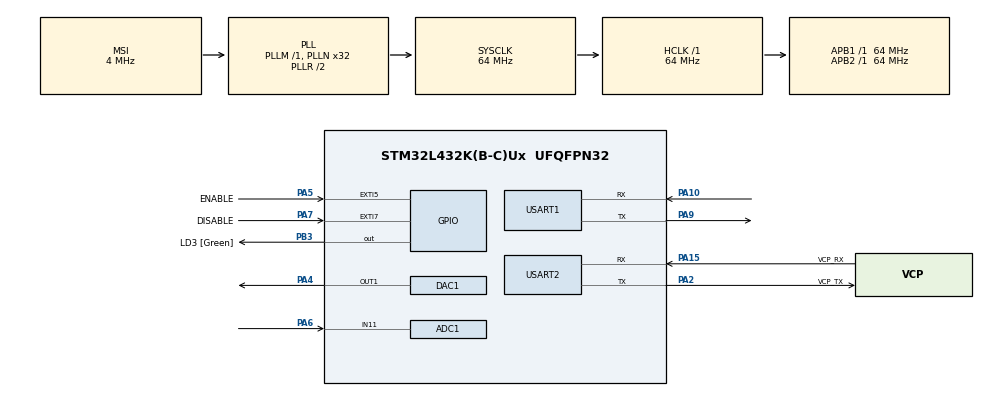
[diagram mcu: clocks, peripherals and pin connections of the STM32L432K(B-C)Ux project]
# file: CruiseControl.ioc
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ADC1.Channel-1\#ChannelRegularConversion=ADC_CHANNEL_11
ADC1.NbrOfConversionFlag=1
ADC1.OffsetNumber-1\#ChannelRegularConversion=ADC_OFFSET_NONE
ADC1.Rank-1\#ChannelRegularConversion=1
ADC1.SamplingTime-1\#ChannelRegularConversion=ADC_SAMPLETIME_2CYCLES_5
ADC1.master=1
Mcu.Family=STM32L4
Mcu.Name=STM32L432K(B-C)Ux
Mcu.Package=UFQFPN32
NVIC.PriorityGroup=NVIC_PRIORITYGROUP_4
PA0.GPIO_Label=MCO [High speed clock in]
PA0.Mode=HSE-External-Clock-Source-for-LittleOrca
PA0.Signal=RCC_CK_IN
PA10.Mode=Asynchronous
PA10.Signal=USART1_RX
PA13\ (JTMS-SWDIO).GPIO_Label=SWDIO
PA13\ (JTMS-SWDIO).Mode=Serial_Wire
PA13\ (JTMS-SWDIO).Signal=SYS_JTMS-SWDIO
PA14\ (JTCK-SWCLK).GPIO_Label=SWCLK
PA14\ (JTCK-SWCLK).Mode=Serial_Wire
PA14\ (JTCK-SWCLK).Signal=SYS_JTCK-SWCLK
PA15\ (JTDI).GPIO_Label=VCP_RX
PA15\ (JTDI).Mode=Asynchronous
PA15\ (JTDI).Signal=USART2_RX
PA2.GPIO_Label=VCP_TX
PA2.Mode=Asynchronous
PA2.Signal=USART2_TX
PA4.Signal=COMP_DAC11_group
PA5.GPIO_Label=ENABLE
PA5.GPIO_PuPd=GPIO_PULLDOWN
PA5.Signal=GPXTI5
PA6.Signal=ADCx_IN11
PA7.GPIO_Label=DISABLE
PA7.Signal=GPXTI7
PA9.Mode=Asynchronous
PA9.Signal=USART1_TX
PB3\ (JTDO-TRACESWO).GPIO_Label=LD3 [Green]
PB3\ (JTDO-TRACESWO).Signal=GPIO_Output
PC14-OSC32_IN\ (PC14).Mode=LSE-External-Oscillator
PC14-OSC32_IN\ (PC14).Signal=RCC_OSC32_IN
PC15-OSC32_OUT\ (PC15).Mode=LSE-External-Oscillator
PC15-OSC32_OUT\ (PC15).Signal=RCC_OSC32_OUT
ProjectManager.HeapSize=0x200
ProjectManager.StackSize=0x400
ProjectManager.TargetToolchain=STM32CubeIDE
RCC.ADCFreq_Value=32000000
RCC.AHBFreq_Value=64000000
RCC.APB1Freq_Value=64000000
RCC.APB1TimFreq_Value=64000000
RCC.APB2Freq_Value=64000000
RCC.APB2TimFreq_Value=64000000
RCC.CortexFreq_Value=64000000
RCC.HCLKFreq_Value=64000000
RCC.HSE_VALUE=8000000
RCC.HSI16_VALUE=16000000
RCC.HSI48_VALUE=48000000
RCC.HSI_VALUE=16000000
RCC.MSI_VALUE=4000000
RCC.PLLMUL=RCC_PLLMUL_4
RCC.PLLN=32
RCC.PLLSAI1N=16
RCC.SYSCLKFreq_VALUE=64000000
RCC.SYSCLKSource=RCC_SYSCLKSOURCE_PLLCLK
RCC.USBFreq_Value=32000000
RCC.VCOOutputFreq_Value=128000000
SH.ADCx_IN11.0=ADC1_IN11,IN11-Single-Ended
SH.COMP_DAC11_group.0=DAC1_OUT1,DAC_OUT1
USART1.VirtualMode-Asynchronous=VM_ASYNC
USART2.VirtualMode-Asynchronous=VM_ASYNC
board=NUCLEO-L432KC

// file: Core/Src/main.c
/* USER CODE BEGIN Header */
/**
  ******************************************************************************
  * @file           : main.c
  * @brief          : Main program body
  ******************************************************************************
  * @attention
  *
  * Copyright (c) 2022 STMicroelectronics.
  * All rights reserved.
  *
  * This software is licensed under terms that can be found in the LICENSE file
  * in the root directory of this software component.
  * If no LICENSE file comes with this software, it is provided AS-IS.
  *
  ******************************************************************************
  */
/* USER CODE END Header */
#include "main.h"
#include "commands_ELM.h"
#include "throttle.h"
#include "stdio.h"
#include "elm327.h"

volatile ADC_HandleTypeDef hadc1;

volatile DAC_HandleTypeDef hdac1;

UART_HandleTypeDef huart1;
UART_HandleTypeDef huart2;

/* USER CODE BEGIN PV */
volatile car_t car_controler;
volatile elm_t dongle;
volatile pid_controller_t pid;

volatile char receive_buffer[64];
/* USER CODE END PV */

void SystemClock_Config(void);
static void MX_GPIO_Init(void);
static void MX_USART2_UART_Init(void);
static void MX_ADC1_Init(void);
static void MX_DAC1_Init(void);
static void MX_USART1_UART_Init(void);

/* USER CODE BEGIN 0 */

int __io_putchar(int ch) {
    uint8_t msg = ch;
    HAL_UART_Transmit(&huart2, &msg, 1, 1000);
    return 1;
}

void timer_configuire()
{

    __HAL_RCC_TIM2_CLK_ENABLE();

    HAL_NVIC_SetPriority(TIM2_IRQn,0,0);
    HAL_NVIC_EnableIRQ(TIM2_IRQn);

    TIM_TypeDef * timer = TIM2;
    timer->EGR = TIM_EGR_UG;
    timer->PSC = 64-1;
    timer->ARR = 5000;
    timer->CR1 = TIM_CR1_ARPE | TIM_CR1_CEN;
    TIM2->DIER =  TIM_DIER_UIE; //generate interrupts

}
/* USER CODE END 0 */

int main(void)
{

  /* MCU Configuration--------------------------------------------------------*/

  /* Reset of all peripherals, Initializes the Flash interface and the Systick. */
  HAL_Init();

  /* Configure the system clock */
  SystemClock_Config();

  /* Initialize all configured peripherals */
  MX_GPIO_Init();
  MX_USART2_UART_Init();
  MX_ADC1_Init();
  MX_DAC1_Init();
  MX_USART1_UART_Init();

  /* USER CODE BEGIN 2 */

    car_controler.throttle_dac_handler = &hdac1;
    car_controler.accelerator_adc_handler = &hadc1;
    car_controler.controler_engaged = 1;
    car_controler.ecu_en_pin = PEDAL_EN_Pin;
    car_controler.ecu_en_port = PEDAL_EN_Port;
    car_controler.state = CAR_STATUS_DIRECT;
    car_controler.controller = &pid;

    HAL_DAC_Start(&hdac1,0);
    HAL_ADC_Start(&hadc1);

    timer_configuire();
  /* USER CODE END 2 */

  /* Infinite loop */
  /* USER CODE BEGIN WHILE */
    car_throttle_handler(&car_controler);

    dongle.huart = &huart1;
    HAL_Delay(2000);
    elm_connect(&dongle);

dongle.rec_buf = receive_buffer;
    for(int i = 0; i<64; i++)
    {
        dongle.rec_buf[i]=0;
    }
    dongle.rec_buf[63] = '\n';

  while (1)
  {

      elm_send_query(&dongle,ELM_QUERY_SPEED,sizeof ELM_QUERY_SPEED,ELM_QUERY_SPEED_DATA_SIZE);

      HAL_Delay(1000);

      printf("Received: %s \r\n", dongle.rec_buf);
      if(dongle.valid_reading) {
          printf("\r\n Speed: %d \r\n", dongle.current_speed);
      }

      /* USER CODE END WHILE */

  }
}

void SystemClock_Config(void)
{
  RCC_OscInitTypeDef RCC_OscInitStruct = {0};
  RCC_ClkInitTypeDef RCC_ClkInitStruct = {0};

  /** Configure the main internal regulator output voltage
  */
  if (HAL_PWREx_ControlVoltageScaling(PWR_REGULATOR_VOLTAGE_SCALE1) != HAL_OK)
  {
    Error_Handler();
  }

  /** Configure LSE Drive Capability
  */
  HAL_PWR_EnableBkUpAccess();
  __HAL_RCC_LSEDRIVE_CONFIG(RCC_LSEDRIVE_LOW);

  /** Initializes the RCC Oscillators according to the specified parameters
  * in the RCC_OscInitTypeDef structure.
  */
  RCC_OscInitStruct.OscillatorType = RCC_OSCILLATORTYPE_LSE|RCC_OSCILLATORTYPE_MSI;
  RCC_OscInitStruct.LSEState = RCC_LSE_ON;
  RCC_OscInitStruct.MSIState = RCC_MSI_ON;
  RCC_OscInitStruct.MSICalibrationValue = 0;
  RCC_OscInitStruct.MSIClockRange = RCC_MSIRANGE_6;
  RCC_OscInitStruct.PLL.PLLState = RCC_PLL_ON;
  RCC_OscInitStruct.PLL.PLLSource = RCC_PLLSOURCE_MSI;
  RCC_OscInitStruct.PLL.PLLM = 1;
  RCC_OscInitStruct.PLL.PLLN = 32;
  RCC_OscInitStruct.PLL.PLLP = RCC_PLLP_DIV7;
  RCC_OscInitStruct.PLL.PLLQ = RCC_PLLQ_DIV2;
  RCC_OscInitStruct.PLL.PLLR = RCC_PLLR_DIV2;
  if (HAL_RCC_OscConfig(&RCC_OscInitStruct) != HAL_OK)
  {
    Error_Handler();
  }

  /** Initializes the CPU, AHB and APB buses clocks
  */
  RCC_ClkInitStruct.ClockType = RCC_CLOCKTYPE_HCLK|RCC_CLOCKTYPE_SYSCLK
                              |RCC_CLOCKTYPE_PCLK1|RCC_CLOCKTYPE_PCLK2;
  RCC_ClkInitStruct.SYSCLKSource = RCC_SYSCLKSOURCE_PLLCLK;
  RCC_ClkInitStruct.AHBCLKDivider = RCC_SYSCLK_DIV1;
  RCC_ClkInitStruct.APB1CLKDivider = RCC_HCLK_DIV1;
  RCC_ClkInitStruct.APB2CLKDivider = RCC_HCLK_DIV1;

  if (HAL_RCC_ClockConfig(&RCC_ClkInitStruct, FLASH_LATENCY_3) != HAL_OK)
  {
    Error_Handler();
  }

  /** Enable MSI Auto calibration
  */
  HAL_RCCEx_EnableMSIPLLMode();
}

static void MX_ADC1_Init(void)
{

  ADC_ChannelConfTypeDef sConfig = {0};

  /** Common config
  */
  hadc1.Instance = ADC1;
  hadc1.Init.ClockPrescaler = ADC_CLOCK_ASYNC_DIV1;
  hadc1.Init.Resolution = ADC_RESOLUTION_12B;
  hadc1.Init.DataAlign = ADC_DATAALIGN_RIGHT;
  hadc1.Init.ScanConvMode = ADC_SCAN_DISABLE;
  hadc1.Init.EOCSelection = ADC_EOC_SINGLE_CONV;
  hadc1.Init.LowPowerAutoWait = DISABLE;
  hadc1.Init.ContinuousConvMode = DISABLE;
  hadc1.Init.NbrOfConversion = 1;
  hadc1.Init.DiscontinuousConvMode = DISABLE;
  hadc1.Init.ExternalTrigConv = ADC_SOFTWARE_START;
  hadc1.Init.ExternalTrigConvEdge = ADC_EXTERNALTRIGCONVEDGE_NONE;
  hadc1.Init.DMAContinuousRequests = DISABLE;
  hadc1.Init.Overrun = ADC_OVR_DATA_PRESERVED;
  hadc1.Init.OversamplingMode = DISABLE;
  if (HAL_ADC_Init(&hadc1) != HAL_OK)
  {
    Error_Handler();
  }

  /** Configure Regular Channel
  */
  sConfig.Channel = ADC_CHANNEL_11;
  sConfig.Rank = ADC_REGULAR_RANK_1;
  sConfig.SamplingTime = ADC_SAMPLETIME_2CYCLES_5;
  sConfig.SingleDiff = ADC_SINGLE_ENDED;
  sConfig.OffsetNumber = ADC_OFFSET_NONE;
  sConfig.Offset = 0;
  if (HAL_ADC_ConfigChannel(&hadc1, &sConfig) != HAL_OK)
  {
    Error_Handler();
  }

}

static void MX_DAC1_Init(void)
{

  DAC_ChannelConfTypeDef sConfig = {0};

  /** DAC Initialization
  */
  hdac1.Instance = DAC1;
  if (HAL_DAC_Init(&hdac1) != HAL_OK)
  {
    Error_Handler();
  }

  /** DAC channel OUT1 config
  */
  sConfig.DAC_SampleAndHold = DAC_SAMPLEANDHOLD_DISABLE;
  sConfig.DAC_Trigger = DAC_TRIGGER_NONE;
  sConfig.DAC_OutputBuffer = DAC_OUTPUTBUFFER_ENABLE;
  sConfig.DAC_ConnectOnChipPeripheral = DAC_CHIPCONNECT_DISABLE;
  sConfig.DAC_UserTrimming = DAC_TRIMMING_FACTORY;
  if (HAL_DAC_ConfigChannel(&hdac1, &sConfig, DAC_CHANNEL_1) != HAL_OK)
  {
    Error_Handler();
  }

}

static void MX_USART1_UART_Init(void)
{

  /* USER CODE BEGIN USART1_Init 0 */
    HAL_NVIC_SetPriority(USART1_IRQn, 2, 2);
    HAL_NVIC_EnableIRQ(USART1_IRQn);
  /* USER CODE END USART1_Init 0 */

  huart1.Instance = USART1;
  huart1.Init.BaudRate = 9600;
  huart1.Init.WordLength = UART_WORDLENGTH_8B;
  huart1.Init.StopBits = UART_STOPBITS_1;
  huart1.Init.Parity = UART_PARITY_NONE;
  huart1.Init.Mode = UART_MODE_TX_RX;
  huart1.Init.HwFlowCtl = UART_HWCONTROL_NONE;
  huart1.Init.OverSampling = UART_OVERSAMPLING_16;
  huart1.Init.OneBitSampling = UART_ONE_BIT_SAMPLE_DISABLE;
  huart1.AdvancedInit.AdvFeatureInit = UART_ADVFEATURE_NO_INIT;
  if (HAL_UART_Init(&huart1) != HAL_OK)
  {
    Error_Handler();
  }

}

static void MX_USART2_UART_Init(void)
{

  huart2.Instance = USART2;
  huart2.Init.BaudRate = 9600;
  huart2.Init.WordLength = UART_WORDLENGTH_8B;
  huart2.Init.StopBits = UART_STOPBITS_1;
  huart2.Init.Parity = UART_PARITY_NONE;
  huart2.Init.Mode = UART_MODE_TX_RX;
  huart2.Init.HwFlowCtl = UART_HWCONTROL_NONE;
  huart2.Init.OverSampling = UART_OVERSAMPLING_16;
  huart2.Init.OneBitSampling = UART_ONE_BIT_SAMPLE_DISABLE;
  huart2.AdvancedInit.AdvFeatureInit = UART_ADVFEATURE_NO_INIT;
  if (HAL_UART_Init(&huart2) != HAL_OK)
  {
    Error_Handler();
  }

}

static void MX_GPIO_Init(void)
{
  GPIO_InitTypeDef GPIO_InitStruct = {0};

  /* GPIO Ports Clock Enable */
  __HAL_RCC_GPIOC_CLK_ENABLE();
  __HAL_RCC_GPIOA_CLK_ENABLE();
  __HAL_RCC_GPIOB_CLK_ENABLE();

  /*Configure GPIO pin Output Level */
  HAL_GPIO_WritePin(LD3_GPIO_Port, LD3_Pin, GPIO_PIN_RESET);

  /*Configure GPIO pin : ENABLE_Pin */
  GPIO_InitStruct.Pin = ENABLE_Pin;
  GPIO_InitStruct.Mode = GPIO_MODE_IT_RISING;
  GPIO_InitStruct.Pull = GPIO_PULLUP;
  HAL_GPIO_Init(ENABLE_GPIO_Port, &GPIO_InitStruct);

  /*Configure GPIO pin : DISABLE_Pin */
  GPIO_InitStruct.Pin = DISABLE_Pin;
  GPIO_InitStruct.Mode = GPIO_MODE_IT_RISING;
  GPIO_InitStruct.Pull = GPIO_PULLUP;
  HAL_GPIO_Init(DISABLE_GPIO_Port, &GPIO_InitStruct);

  /*Configure GPIO pin : LD3_Pin */
  GPIO_InitStruct.Pin = LD3_Pin;
  GPIO_InitStruct.Mode = GPIO_MODE_OUTPUT_PP;
  GPIO_InitStruct.Pull = GPIO_NOPULL;
  GPIO_InitStruct.Speed = GPIO_SPEED_FREQ_LOW;
  HAL_GPIO_Init(LD3_GPIO_Port, &GPIO_InitStruct);

    GPIO_InitStruct.Pin = PEDAL_EN_Pin;
    GPIO_InitStruct.Mode = GPIO_MODE_OUTPUT_PP;
    GPIO_InitStruct.Pull = GPIO_NOPULL;
    GPIO_InitStruct.Speed = GPIO_SPEED_FREQ_LOW;
    HAL_GPIO_Init(PEDAL_EN_Port, &GPIO_InitStruct);

    HAL_NVIC_SetPriority(EXTI9_5_IRQn,0,0);
    HAL_NVIC_EnableIRQ(EXTI9_5_IRQn);

}

/* USER CODE BEGIN 4 */
void TIM2_IRQHandler(void)  //main refresh loop
{
    //HAL_GPIO_TogglePin(GPIOB,GPIO_PIN_3);
    car_throttle_handler(&car_controler);

    TIM2->SR = ~TIM_SR_UIF;
}

void HAL_UART_RxCpltCallback(UART_HandleTypeDef *huart){
    HAL_GPIO_WritePin(LD3_GPIO_Port,LD3_Pin,1);

    for(int i = 0; i<64; i++)
    {
        if(dongle.rec_buf[i]==0 || dongle.rec_buf[i]=='\r')
        {
            dongle.rec_buf[i] = ' ';
        }
    }

    elm_parse_speed(&dongle);
    if(&dongle.valid_reading)
    {
        uint32_t time = HAL_GetTick();
        dongle.velocity_read_interval = time-dongle.velocity_read_timestamp;
        dongle.velocity_read_timestamp = time;

    }
}

/* USER CODE END 4 */

void Error_Handler(void)
{
  __disable_irq();
  while (1)
  {
  }
}
